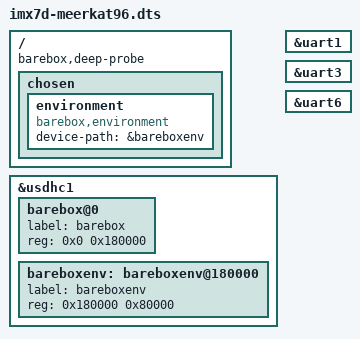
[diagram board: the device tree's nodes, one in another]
// SPDX-License-Identifier: GPL-2.0+ OR MIT
#include <arm/nxp/imx/imx7d-meerkat96.dts>

/ {
	barebox,deep-probe;

	chosen {
		environment {
			compatible = "barebox,environment";
			device-path = &bareboxenv;
		};
	};
};

&usdhc1 {
	#address-cells = <1>;
	#size-cells = <1>;

	barebox@0 {
		label = "barebox";
		reg = <0x0 0x180000>;
	};

	bareboxenv: bareboxenv@180000 {
		label = "bareboxenv";
		reg = <0x180000 0x80000>;
	};
};

/* FIXME: barebox serial is broken when barebox applies requested reparenting */
&uart1 {
	/delete-property/ assigned-clocks;
	/delete-property/ assigned-clock-parents;
};

&uart3  {
	/delete-property/ assigned-clocks;
	/delete-property/ assigned-clock-parents;
};

&uart6 {
	/delete-property/ assigned-clocks;
	/delete-property/ assigned-clock-parents;
};
